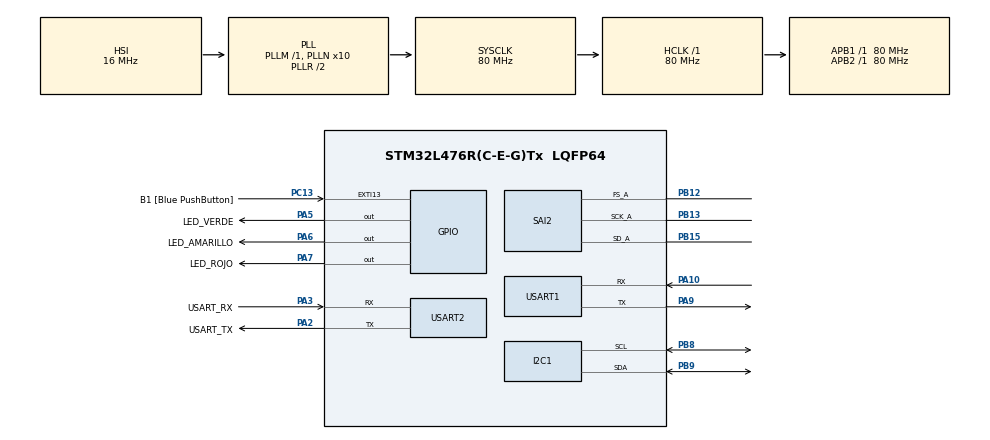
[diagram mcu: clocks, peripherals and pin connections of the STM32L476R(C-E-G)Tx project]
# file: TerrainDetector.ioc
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Dma.Request0=SAI2_A
Dma.SAI2_A.0.Direction=DMA_PERIPH_TO_MEMORY
Dma.SAI2_A.0.Instance=DMA1_Channel6
Dma.SAI2_A.0.MemDataAlignment=DMA_MDATAALIGN_WORD
Dma.SAI2_A.0.MemInc=DMA_MINC_ENABLE
Dma.SAI2_A.0.Mode=DMA_CIRCULAR
Dma.SAI2_A.0.PeriphDataAlignment=DMA_PDATAALIGN_WORD
Dma.SAI2_A.0.PeriphInc=DMA_PINC_DISABLE
Dma.SAI2_A.0.Priority=DMA_PRIORITY_LOW
I2C1.Timing=0x10D19CE4
Mcu.Family=STM32L4
Mcu.Name=STM32L476R(C-E-G)Tx
Mcu.Package=LQFP64
NVIC.DMA1_Channel6_IRQn=true\:0\:0\:false\:false\:true\:false\:true\:true
NVIC.PriorityGroup=NVIC_PRIORITYGROUP_4
PA10.Mode=Asynchronous
PA10.Signal=USART1_RX
PA13\ (JTMS-SWDIO).GPIO_Label=TMS
PA13\ (JTMS-SWDIO).Mode=Serial_Wire
PA13\ (JTMS-SWDIO).Signal=SYS_JTMS-SWDIO
PA14\ (JTCK-SWCLK).GPIO_Label=TCK
PA14\ (JTCK-SWCLK).Mode=Serial_Wire
PA14\ (JTCK-SWCLK).Signal=SYS_JTCK-SWCLK
PA2.GPIO_Label=USART_TX
PA2.GPIO_Mode=GPIO_MODE_AF_PP
PA2.GPIO_PuPd=GPIO_NOPULL
PA2.GPIO_Speed=GPIO_SPEED_FREQ_VERY_HIGH
PA2.Mode=Asynchronous
PA2.Signal=USART2_TX
PA3.GPIO_Label=USART_RX
PA3.GPIO_Mode=GPIO_MODE_AF_PP
PA3.GPIO_PuPd=GPIO_NOPULL
PA3.GPIO_Speed=GPIO_SPEED_FREQ_VERY_HIGH
PA3.Mode=Asynchronous
PA3.Signal=USART2_RX
PA5.GPIO_Label=LED_VERDE
PA5.GPIO_ModeDefaultOutputPP=GPIO_MODE_OUTPUT_PP
PA5.GPIO_PuPd=GPIO_NOPULL
PA5.GPIO_Speed=GPIO_SPEED_FREQ_LOW
PA5.Signal=GPIO_Output
PA6.GPIO_Label=LED_AMARILLO
PA6.Signal=GPIO_Output
PA7.GPIO_Label=LED_ROJO
PA7.Signal=GPIO_Output
PA9.Mode=Asynchronous
PA9.Signal=USART1_TX
PB12.Mode=SAI_A_Master
PB12.Signal=SAI2_FS_A
PB13.Mode=SAI_A_Master
PB13.Signal=SAI2_SCK_A
PB15.Mode=SAI_A_Master
PB15.Signal=SAI2_SD_A
PB3\ (JTDO-TRACESWO).GPIO_Label=SWO
PB3\ (JTDO-TRACESWO).Signal=SYS_JTDO-SWO
PB8.Mode=I2C
PB8.Signal=I2C1_SCL
PB9.Mode=I2C
PB9.Signal=I2C1_SDA
PC13.GPIO_Label=B1 [Blue PushButton]
PC13.GPIO_ModeDefaultEXTI=GPIO_MODE_IT_FALLING
PC13.GPIO_PuPd=GPIO_NOPULL
PC13.Signal=GPXTI13
PC14-OSC32_IN\ (PC14).Mode=LSE-External-Oscillator
PC14-OSC32_IN\ (PC14).Signal=RCC_OSC32_IN
PC15-OSC32_OUT\ (PC15).Mode=LSE-External-Oscillator
PC15-OSC32_OUT\ (PC15).Signal=RCC_OSC32_OUT
PH0-OSC_IN\ (PH0).Signal=RCC_OSC_IN
PH1-OSC_OUT\ (PH1).Signal=RCC_OSC_OUT
ProjectManager.HeapSize=0x200
ProjectManager.StackSize=0x400
ProjectManager.TargetToolchain=STM32CubeIDE
RCC.ADCFreq_Value=64000000
RCC.AHBFreq_Value=80000000
RCC.APB1Freq_Value=80000000
RCC.APB1TimFreq_Value=80000000
RCC.APB2Freq_Value=80000000
RCC.APB2TimFreq_Value=80000000
RCC.CortexFreq_Value=80000000
RCC.HCLKFreq_Value=80000000
RCC.HSE_VALUE=8000000
RCC.HSI_VALUE=16000000
RCC.MSI_VALUE=4000000
RCC.PLLN=10
RCC.PLLSourceVirtual=RCC_PLLSOURCE_HSI
RCC.PREFETCH_ENABLE=1
RCC.SYSCLKFreq_VALUE=80000000
RCC.SYSCLKSource=RCC_SYSCLKSOURCE_PLLCLK
RCC.USBFreq_Value=64000000
RCC.VCOOutputFreq_Value=160000000
SAI2.AudioFrequency-SAI_A_Master=SAI_AUDIO_FREQUENCY_16K
SAI2.AudioMode-SAI_A_Master=SAI_MODEMASTER_RX
SAI2.BasicDataSize-SAI_A_Master=SAI_PROTOCOL_DATASIZE_24BIT
SAI2.ErrorAudioFreq-SAI_A_Master=11.6 %
SAI2.InitProtocol-SAI_A_Master=Enable
SAI2.Instance-SAI_A_Master=SAI$Index_Block_A
SAI2.MClockEnable-SAI_A_Master=SAI_MASTERCLOCK_DISABLE
SAI2.RealAudioFreq-SAI_A_Master=17.857 KHz
SAI2.VirtualMode-SAI_A_Master=VM_MASTER
SAI2.VirtualProtocol-SAI_A_BASIC=VM_BASIC_PROTOCOL
USART1.VirtualMode-Asynchronous=VM_ASYNC
USART2.VirtualMode-Asynchronous=VM_ASYNC
VP_SAI2_VP_$IpInstance_SAIA_SAI_BASIC.Mode=SAI_A_BASIC
board=NUCLEO-L476RG

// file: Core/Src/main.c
/* USER CODE BEGIN Header */
/**
  ******************************************************************************
  * @file           : main.c
  * @brief          : Main program body
  ******************************************************************************
  * @attention
  *
  * Copyright (c) 2026 STMicroelectronics.
  * All rights reserved.
  *
  * This software is licensed under terms that can be found in the LICENSE file
  * in the root directory of this software component.
  * If no LICENSE file comes with this software, it is provided AS-IS.
  *
  ******************************************************************************
  */
/* USER CODE END Header */
#include "main.h"

/* USER CODE BEGIN Includes */
#include "LSM6DSL.h"
#include <stdio.h>
#include <string.h>
#include "NanoEdgeAI.h"
/* USER CODE END Includes */

I2C_HandleTypeDef hi2c1;

SAI_HandleTypeDef hsai_BlockA2;
DMA_HandleTypeDef hdma_sai2_a;

UART_HandleTypeDef huart1;
UART_HandleTypeDef huart2;

/* USER CODE BEGIN PV */
/* Declaraciones de NanoEdge AI */
float input_signal[NEAI_INPUT_SIGNAL_LENGTH * NEAI_INPUT_AXIS_NUMBER];
float probabilities[NEAI_NUMBER_OF_CLASSES];
int id_class = 0;

/* Control de programa y logging */
volatile uint8_t programa_corriendo = 0;
uint8_t prev_programa_corriendo = 0;
uint32_t ultimo_tiempo_boton = 0;
uint32_t last_log_tick = 0;
uint32_t session_start_tick = 0;
uint32_t travel_time_ms = 0;

#define MAX_SAMPLES 5000
uint8_t status_buffer[MAX_SAMPLES];
uint16_t sample_count = 0;
/* USER CODE END PV */

void SystemClock_Config(void);
static void MX_GPIO_Init(void);
static void MX_DMA_Init(void);
static void MX_USART2_UART_Init(void);
static void MX_USART1_UART_Init(void);
static void MX_I2C1_Init(void);
static void MX_SAI2_Init(void);

/* USER CODE BEGIN 0 */
int __io_putchar(int ch)
{
	uint8_t c[1];
	c[0] = ch & 0x00FF;
	HAL_UART_Transmit(&huart2, &*c, 1, 10);
	return ch;
}
/* USER CODE END 0 */

int main(void)
{

  /* MCU Configuration--------------------------------------------------------*/

  /* Reset of all peripherals, Initializes the Flash interface and the Systick. */
  HAL_Init();

  /* Configure the system clock */
  SystemClock_Config();

  /* Initialize all configured peripherals */
  MX_GPIO_Init();
  MX_DMA_Init();
  MX_USART2_UART_Init();
  MX_USART1_UART_Init();
  MX_I2C1_Init();
  MX_SAI2_Init();
  /* USER CODE BEGIN 2 */

  LSM6DSL_Init();
  MPU6050_Init();

  // Inicialización de NanoEdge AI (Sin parámetros en esta versión de la lib)
  enum neai_state neai_status = neai_classification_init();
  if (neai_status != NEAI_OK) {
	  HAL_UART_Transmit(&huart2, (uint8_t*)"NEAI Init Error\n", 16, 100);
  }

  /* USER CODE END 2 */

  /* Infinite loop */
  /* USER CODE BEGIN WHILE */
  while (1)
  {
        // Detectar transición de Parado -> Iniciado
        if (programa_corriendo == 1 && prev_programa_corriendo == 0) {
            HAL_GPIO_WritePin(GPIOA, LED_BLANCO_Pin, GPIO_PIN_SET); // Encender monitoreo
            sample_count = 0;
            session_start_tick = HAL_GetTick(); // Inicio del viaje
            last_log_tick = session_start_tick;
            prev_programa_corriendo = 1;
        }

        // Detectar transición de Iniciado -> Parado (Envío de lote)
        if (programa_corriendo == 0 && prev_programa_corriendo == 1) {
            travel_time_ms = HAL_GetTick() - session_start_tick; // Duración total
            HAL_GPIO_WritePin(GPIOA, LED_BLANCO_Pin, GPIO_PIN_RESET); // Apagar monitoreo
            HAL_GPIO_WritePin(GPIOA, LED_VERDE_Pin|LED_AMARILLO_Pin|LED_ROJO_Pin, GPIO_PIN_RESET);

            HAL_UART_Transmit(&huart1, (uint8_t*)"START_BATCH\n", 12, 100);
            for (uint16_t i = 0; i < sample_count; i++) {
                const char* name = neai_get_class_name(status_buffer[i]);
                char msg[32];
                snprintf(msg, sizeof(msg), "DET:%s\n", name ? name : "UNKNOWN");
                HAL_UART_Transmit(&huart1, (uint8_t*)msg, strlen(msg), 100);
                HAL_Delay(1); // Sincronización: 1ms para no saturar el puente WiFi
            }

            char end_msg[64];
            snprintf(end_msg, sizeof(end_msg), "END_BATCH:%lu\n", travel_time_ms);
            HAL_UART_Transmit(&huart1, (uint8_t*)end_msg, strlen(end_msg), 100);

            sample_count = 0;
            prev_programa_corriendo = 0;
        }

        if (programa_corriendo)
        {
            float accel[3];

            // 1. Captura de datos: Llenado del buffer (x, y, z)
            for(uint16_t i=0; i < NEAI_INPUT_SIGNAL_LENGTH; i++){
                MPU6050_ReadAccel(accel);

                input_signal[3*i] = accel[0];
                input_signal[3*i+1] = accel[1];
                input_signal[3*i+2] = accel[2];

                // Logging cada 100ms durante la captura
                if (HAL_GetTick() - last_log_tick >= 100) {
                    if (sample_count < MAX_SAMPLES) {
                        status_buffer[sample_count++] = (uint8_t)id_class;
                    }
                    last_log_tick = HAL_GetTick();
                }

                // Frecuencia de muestreo (10ms -> 100Hz)
                HAL_Delay(10);
                if (!programa_corriendo) break;
            }

            if (!programa_corriendo) continue;

            // 2. Ejecutar Inferencia local en la STM32
            neai_classification(input_signal, probabilities, &id_class);

            // 3. Lógica de LEDs
            HAL_GPIO_WritePin(GPIOA, LED_VERDE_Pin|LED_AMARILLO_Pin|LED_ROJO_Pin, GPIO_PIN_RESET);
            const char* terrain_name = neai_get_class_name(id_class);

            if (terrain_name != NULL) {
                if (strcmp(terrain_name, "LISO") == 0) {
                    HAL_GPIO_WritePin(GPIOA, LED_VERDE_Pin, GPIO_PIN_SET);
                }
                else if (strcmp(terrain_name, "SUELO PIEDRA") == 0) {
                    HAL_GPIO_WritePin(GPIOA, LED_AMARILLO_Pin, GPIO_PIN_SET);
                }
                else if (strcmp(terrain_name, "ASFALTO_RUGOSO") == 0) {
                    HAL_GPIO_WritePin(GPIOA, LED_ROJO_Pin, GPIO_PIN_SET);
                }
            }

            // Pequeña pausa para no saturar CPU, manteniendo el log de 100ms
            for(int j=0; j<10; j++) {
                if (HAL_GetTick() - last_log_tick >= 100) {
                    if (sample_count < MAX_SAMPLES) status_buffer[sample_count++] = (uint8_t)id_class;
                    last_log_tick = HAL_GetTick();
                }
                HAL_Delay(10);
                if (!programa_corriendo) break;
            }
        }
        else
        {
            // Espera pasiva para no consumir recursos innecesarios
            HAL_Delay(100);
        }

    /* USER CODE END WHILE */

  }
}

void SystemClock_Config(void)
{
  RCC_OscInitTypeDef RCC_OscInitStruct = {0};
  RCC_ClkInitTypeDef RCC_ClkInitStruct = {0};

  /** Configure the main internal regulator output voltage
  */
  if (HAL_PWREx_ControlVoltageScaling(PWR_REGULATOR_VOLTAGE_SCALE1) != HAL_OK)
  {
    Error_Handler();
  }

  /** Initializes the RCC Oscillators according to the specified parameters
  * in the RCC_OscInitTypeDef structure.
  */
  RCC_OscInitStruct.OscillatorType = RCC_OSCILLATORTYPE_HSI;
  RCC_OscInitStruct.HSIState = RCC_HSI_ON;
  RCC_OscInitStruct.HSICalibrationValue = RCC_HSICALIBRATION_DEFAULT;
  RCC_OscInitStruct.PLL.PLLState = RCC_PLL_ON;
  RCC_OscInitStruct.PLL.PLLSource = RCC_PLLSOURCE_HSI;
  RCC_OscInitStruct.PLL.PLLM = 1;
  RCC_OscInitStruct.PLL.PLLN = 10;
  RCC_OscInitStruct.PLL.PLLP = RCC_PLLP_DIV7;
  RCC_OscInitStruct.PLL.PLLQ = RCC_PLLQ_DIV2;
  RCC_OscInitStruct.PLL.PLLR = RCC_PLLR_DIV2;
  if (HAL_RCC_OscConfig(&RCC_OscInitStruct) != HAL_OK)
  {
    Error_Handler();
  }

  /** Initializes the CPU, AHB and APB buses clocks
  */
  RCC_ClkInitStruct.ClockType = RCC_CLOCKTYPE_HCLK|RCC_CLOCKTYPE_SYSCLK
                              |RCC_CLOCKTYPE_PCLK1|RCC_CLOCKTYPE_PCLK2;
  RCC_ClkInitStruct.SYSCLKSource = RCC_SYSCLKSOURCE_PLLCLK;
  RCC_ClkInitStruct.AHBCLKDivider = RCC_SYSCLK_DIV1;
  RCC_ClkInitStruct.APB1CLKDivider = RCC_HCLK_DIV1;
  RCC_ClkInitStruct.APB2CLKDivider = RCC_HCLK_DIV1;

  if (HAL_RCC_ClockConfig(&RCC_ClkInitStruct, FLASH_LATENCY_4) != HAL_OK)
  {
    Error_Handler();
  }
}

static void MX_I2C1_Init(void)
{

  hi2c1.Instance = I2C1;
  hi2c1.Init.Timing = 0x10D19CE4;
  hi2c1.Init.OwnAddress1 = 0;
  hi2c1.Init.AddressingMode = I2C_ADDRESSINGMODE_7BIT;
  hi2c1.Init.DualAddressMode = I2C_DUALADDRESS_DISABLE;
  hi2c1.Init.OwnAddress2 = 0;
  hi2c1.Init.OwnAddress2Masks = I2C_OA2_NOMASK;
  hi2c1.Init.GeneralCallMode = I2C_GENERALCALL_DISABLE;
  hi2c1.Init.NoStretchMode = I2C_NOSTRETCH_DISABLE;
  if (HAL_I2C_Init(&hi2c1) != HAL_OK)
  {
    Error_Handler();
  }

  /** Configure Analogue filter
  */
  if (HAL_I2CEx_ConfigAnalogFilter(&hi2c1, I2C_ANALOGFILTER_ENABLE) != HAL_OK)
  {
    Error_Handler();
  }

  /** Configure Digital filter
  */
  if (HAL_I2CEx_ConfigDigitalFilter(&hi2c1, 0) != HAL_OK)
  {
    Error_Handler();
  }

}

static void MX_SAI2_Init(void)
{

  hsai_BlockA2.Instance = SAI2_Block_A;
  hsai_BlockA2.Init.AudioMode = SAI_MODEMASTER_RX;
  hsai_BlockA2.Init.Synchro = SAI_ASYNCHRONOUS;
  hsai_BlockA2.Init.OutputDrive = SAI_OUTPUTDRIVE_DISABLE;
  hsai_BlockA2.Init.NoDivider = SAI_MASTERDIVIDER_ENABLE;
  hsai_BlockA2.Init.FIFOThreshold = SAI_FIFOTHRESHOLD_EMPTY;
  hsai_BlockA2.Init.AudioFrequency = SAI_AUDIO_FREQUENCY_16K;
  hsai_BlockA2.Init.SynchroExt = SAI_SYNCEXT_DISABLE;
  hsai_BlockA2.Init.MonoStereoMode = SAI_STEREOMODE;
  hsai_BlockA2.Init.CompandingMode = SAI_NOCOMPANDING;
  if (HAL_SAI_InitProtocol(&hsai_BlockA2, SAI_I2S_STANDARD, SAI_PROTOCOL_DATASIZE_24BIT, 2) != HAL_OK)
  {
    Error_Handler();
  }

}

static void MX_USART1_UART_Init(void)
{

  huart1.Instance = USART1;
  huart1.Init.BaudRate = 115200;
  huart1.Init.WordLength = UART_WORDLENGTH_8B;
  huart1.Init.StopBits = UART_STOPBITS_1;
  huart1.Init.Parity = UART_PARITY_NONE;
  huart1.Init.Mode = UART_MODE_TX_RX;
  huart1.Init.HwFlowCtl = UART_HWCONTROL_NONE;
  huart1.Init.OverSampling = UART_OVERSAMPLING_16;
  huart1.Init.OneBitSampling = UART_ONE_BIT_SAMPLE_DISABLE;
  huart1.AdvancedInit.AdvFeatureInit = UART_ADVFEATURE_NO_INIT;
  if (HAL_UART_Init(&huart1) != HAL_OK)
  {
    Error_Handler();
  }

}

static void MX_USART2_UART_Init(void)
{

  huart2.Instance = USART2;
  huart2.Init.BaudRate = 115200;
  huart2.Init.WordLength = UART_WORDLENGTH_8B;
  huart2.Init.StopBits = UART_STOPBITS_1;
  huart2.Init.Parity = UART_PARITY_NONE;
  huart2.Init.Mode = UART_MODE_TX_RX;
  huart2.Init.HwFlowCtl = UART_HWCONTROL_NONE;
  huart2.Init.OverSampling = UART_OVERSAMPLING_16;
  huart2.Init.OneBitSampling = UART_ONE_BIT_SAMPLE_DISABLE;
  huart2.AdvancedInit.AdvFeatureInit = UART_ADVFEATURE_NO_INIT;
  if (HAL_UART_Init(&huart2) != HAL_OK)
  {
    Error_Handler();
  }

}

static void MX_DMA_Init(void)
{

  /* DMA controller clock enable */
  __HAL_RCC_DMA1_CLK_ENABLE();

  /* DMA interrupt init */
  /* DMA1_Channel6_IRQn interrupt configuration */
  HAL_NVIC_SetPriority(DMA1_Channel6_IRQn, 0, 0);
  HAL_NVIC_EnableIRQ(DMA1_Channel6_IRQn);

}

static void MX_GPIO_Init(void)
{
  GPIO_InitTypeDef GPIO_InitStruct = {0};

  /* GPIO Ports Clock Enable */
  __HAL_RCC_GPIOC_CLK_ENABLE();
  __HAL_RCC_GPIOH_CLK_ENABLE();
  __HAL_RCC_GPIOA_CLK_ENABLE();
  __HAL_RCC_GPIOB_CLK_ENABLE();

  /*Configure GPIO pin Output Level */
  HAL_GPIO_WritePin(GPIOA, LED_VERDE_Pin|LED_AMARILLO_Pin|LED_ROJO_Pin|LED_BLANCO_Pin, GPIO_PIN_RESET);

  /*Configure GPIO pin : B1_Pin */
  GPIO_InitStruct.Pin = B1_Pin;
  GPIO_InitStruct.Mode = GPIO_MODE_IT_FALLING;
  GPIO_InitStruct.Pull = GPIO_NOPULL;
  HAL_GPIO_Init(B1_GPIO_Port, &GPIO_InitStruct);

  /*Configure GPIO pins : LED_VERDE_Pin LED_AMARILLO_Pin LED_ROJO_Pin LED_BLANCO_Pin */
  GPIO_InitStruct.Pin = LED_VERDE_Pin|LED_AMARILLO_Pin|LED_ROJO_Pin|LED_BLANCO_Pin;
  GPIO_InitStruct.Mode = GPIO_MODE_OUTPUT_PP;
  GPIO_InitStruct.Pull = GPIO_NOPULL;
  GPIO_InitStruct.Speed = GPIO_SPEED_FREQ_LOW;
  HAL_GPIO_Init(GPIOA, &GPIO_InitStruct);

  /* EXTI interrupt init*/
  HAL_NVIC_SetPriority(EXTI15_10_IRQn, 0, 0);
  HAL_NVIC_EnableIRQ(EXTI15_10_IRQn);

}

/* USER CODE BEGIN 4 */
void HAL_GPIO_EXTI_Callback(uint16_t GPIO_Pin)
{
    if(GPIO_Pin == B1_Pin)
    {
        // Antirrebote de 250ms
        if (HAL_GetTick() - ultimo_tiempo_boton > 250)
        {
            programa_corriendo = !programa_corriendo; // Cambia entre encendido/apagado
            ultimo_tiempo_boton = HAL_GetTick();
        }
    }
}
/* USER CODE END 4 */

void Error_Handler(void)
{
  __disable_irq();
  while (1)
  {
  }
}
